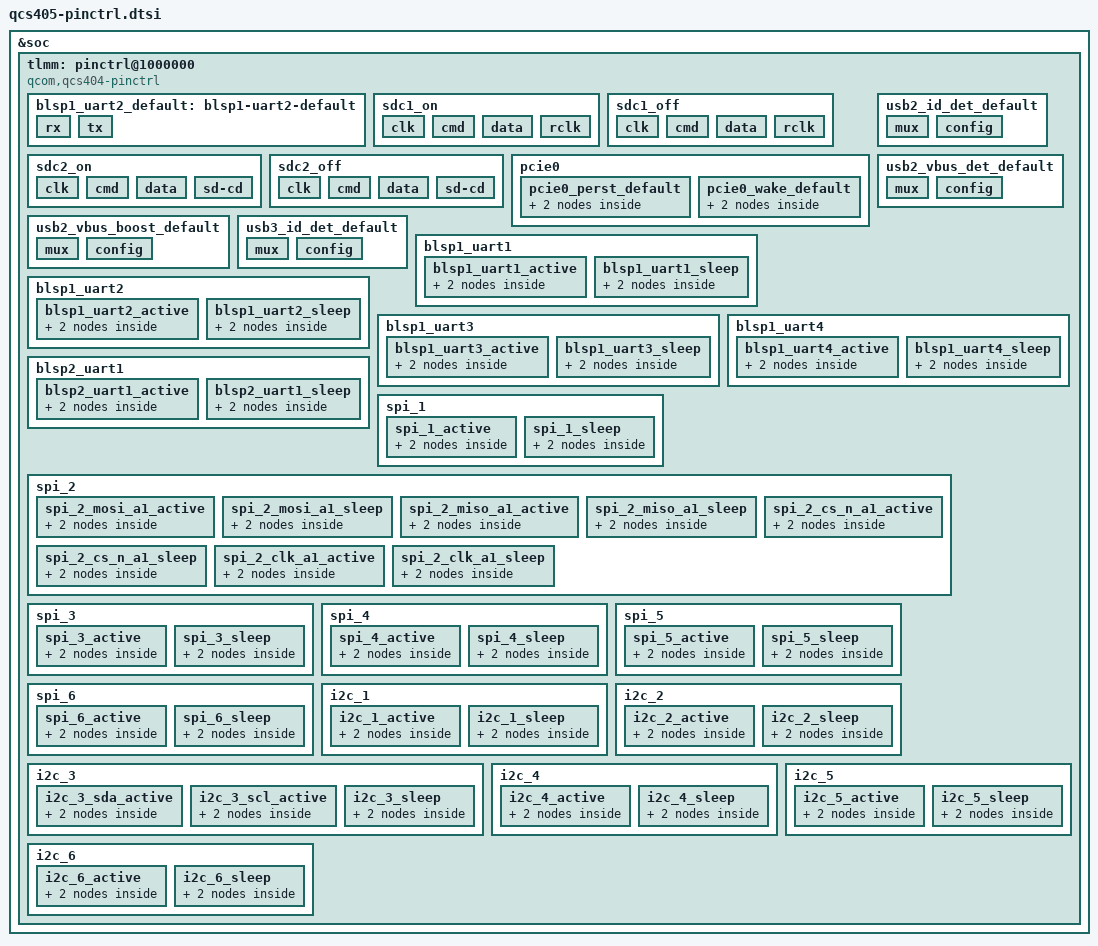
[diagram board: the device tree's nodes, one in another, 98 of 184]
&soc {
	tlmm: pinctrl@1000000 {
		compatible = "qcom,qcs404-pinctrl";
		reg = <0x01000000 0x200000>,
		      <0x01300000 0x200000>,
		      <0x07b00000 0x200000>;
		reg-names = "south", "north", "east";
		interrupts = <GIC_SPI 208 IRQ_TYPE_LEVEL_HIGH>;
		interrupt-controller;
		#interrupt-cells = <2>;
		gpio-ranges = <&tlmm 0 0 120>;
		gpio-controller;
		#gpio-cells = <2>;
		wakeup-parent = <&wakegic>;

		blsp1_uart2_default: blsp1-uart2-default {
			rx {
				pins = "gpio18";
				function = "blsp_uart_rx_a2";
			};

			tx {
				pins = "gpio17";
				function = "blsp_uart_tx_a2";
			};
		};

		sdc1_on: sdc1_on {
			clk {
				pins = "sdc1_clk";
				bias-disable;
				drive-strength = <16>;
			};

			cmd {
				pins = "sdc1_cmd";
				bias-pull-up;
				drive-strength = <10>;
			};

			data {
				pins = "sdc1_data";
				bias-pull-up;
				drive-strength = <10>;
			};

			rclk {
				pins = "sdc1_rclk";
				bias-pull-down;
			};
		};

		sdc1_off: sdc1_off {
			clk {
				pins = "sdc1_clk";
				bias-disable;
				drive-strength = <2>;
			};

			cmd {
				pins = "sdc1_cmd";
				bias-pull-up;
				drive-strength = <2>;
			};

			data {
				pins = "sdc1_data";
				bias-pull-up;
				drive-strength = <2>;
			};

			rclk {
				pins = "sdc1_rclk";
				bias-pull-down;
			};
		};

		sdc2_on: sdc2_on {
			clk {
				pins = "sdc2_clk";
				bias-disable;
				drive-strength = <16>;
			};

			cmd {
				pins = "sdc2_cmd";
				bias-pull-up;
				drive-strength = <10>;
			};

			data {
				pins = "sdc2_data";
				bias-pull-up;
				drive-strength = <10>;
			};

			sd-cd {
				pins = "gpio21";
				bias-pull-up;
				drive-strength = <2>;
			};
		};

		sdc2_off: sdc2_off {
			clk {
				pins = "sdc2_clk";
				bias-disable;
				drive-strength = <2>;
			};

			cmd {
				pins = "sdc2_cmd";
				bias-pull-up;
				drive-strength = <2>;
			};

			data {
				pins = "sdc2_data";
				bias-pull-up;
				drive-strength = <2>;
			};

			sd-cd {
				pins = "gpio21";
				bias-disable;
				drive-strength = <2>;
			};
		};

		pcie0 {
			pcie0_perst_default: pcie0_perst_default {
				mux {
					pins = "gpio43";
					function = "gpio";
				};

				config {
					pins = "gpio43";
					drive-strength = <2>;
					bias-disable;
				};
			};

			pcie0_wake_default: pcie0_wake_default {
				mux {
					pins = "gpio21";
					function = "gpio";
				};

				config {
					pins = "gpio21";
					drive-strength = <2>;
					bias-pull-down;
				};
			};
		};

		usb2_id_det_default: usb2_id_det_default {
			mux {
				pins = "gpio53";
				function = "gpio";
			};

			config {
				pins = "gpio53";
				drive-strength = <2>;
				bias-pull-up;
				input-enable;
			};
		};

		usb2_vbus_boost_default: usb2_vbus_boost_default {
			mux {
				pins = "gpio108";
				function = "gpio";
			};

			config {
				pins = "gpio108";
				drive-strength = <2>;
				bias-pull-down;
				output-low;
			};
		};

		usb2_vbus_det_default: usb2_vbus_det_default {
			mux {
				pins = "gpio116";
				function = "gpio";
			};

			config {
				pins = "gpio116";
				drive-strength = <2>;
				bias-pull-down;
				input-enable;
			};
		};

		usb3_id_det_default: usb3_id_det_default {
			mux {
				pins = "gpio113";
				function = "gpio";
			};

			config {
				pins = "gpio113";
				drive-strength = <2>;
				bias-pull-up;
				input-enable;
			};
		};

		/* UART configuration */
		blsp1_uart1 {
			blsp1_uart1_active: blsp1_uart1_active {
				mux {
					pins = "gpio30", "gpio31";
					function = "blsp_uart0";
				};

				config {
					pins = "gpio30", "gpio31";
					drive-strength = <2>;
					bias-disable;
				};
			};

			blsp1_uart1_sleep: blsp1_uart1_sleep {
				mux {
					pins = "gpio30", "gpio31";
					function = "gpio";
				};

				config {
					pins = "gpio30", "gpio31";
					drive-strength = <2>;
					bias-disable;
				};
			};
		};

		blsp1_uart2 {
			blsp1_uart2_active: blsp1_uart2_active {
				mux {
					pins = "gpio22", "gpio23";
					function = "blsp_uart1";
				};

				config {
					pins = "gpio22", "gpio23";
					drive-strength = <2>;
					bias-disable;
				};
			};

			blsp1_uart2_sleep: blsp1_uart2_sleep {
				mux {
					pins = "gpio22", "gpio23";
					function = "gpio";
				};

				config {
					pins = "gpio22", "gpio23";
					drive-strength = <2>;
					bias-disable;
				};
			};
		};

		blsp1_uart3 {
			blsp1_uart3_active: blsp1_uart3_active {
				mux {
					pins = "gpio17", "gpio18",
						"gpio19", "gpio20";
					function = "blsp_uart2";
				};

				config {
					pins = "gpio17", "gpio18",
						"gpio19", "gpio20";
					drive-strength = <2>;
					bias-disable;
				};
			};

			blsp1_uart3_sleep: blsp1_uart3_sleep {
				mux {
					pins = "gpio17", "gpio18",
						"gpio19", "gpio20";
					function = "gpio";
				};

				config {
					pins = "gpio17", "gpio18",
						"gpio19", "gpio20";
					drive-strength = <2>;
					bias-disable;
				};
			};
		};

		blsp1_uart4 {
			blsp1_uart4_active: blsp1_uart4_active {
				mux {
					pins = "gpio82", "gpio83";
					function = "blsp_uart3";
				};

				config {
					pins = "gpio82", "gpio83";
					drive-strength = <2>;
					bias-disable;
				};
			};

			blsp1_uart4_sleep: blsp1_uart4_sleep {
				mux {
					pins = "gpio82", "gpio83";
					function = "gpio";
				};

				config {
					pins = "gpio82", "gpio83";
					drive-strength = <2>;
					bias-disable;
				};
			};
		};

		blsp2_uart1 {
			blsp2_uart1_active: blsp2_uart1_active {
				mux {
					pins = "gpio26", "gpio27",
						"gpio28", "gpio29";
					function = "blsp_uart5";
				};

				config {
					pins = "gpio26", "gpio27",
						"gpio28", "gpio29";
					drive-strength = <2>;
					bias-disable;
				};
			};

			blsp2_uart1_sleep: blsp2_uart1_sleep {
				mux {
					pins = "gpio26", "gpio27",
						"gpio28", "gpio29";
					function = "gpio";
				};

				config {
					pins = "gpio26", "gpio27",
						"gpio28", "gpio29";
					drive-strength = <2>;
					bias-disable;
				};
			};
		};

		/* SPI CONFIGURATION */
		spi_1 {
			spi_1_active: spi_1_active {
				mux {
					pins = "gpio30", "gpio31",
						"gpio32", "gpio33";
					function = "blsp_spi0";
				};

				config {
					pins = "gpio30", "gpio31",
						"gpio32", "gpio33";
					drive-strength = <6>;
					bias-disable;
				};
			};

			spi_1_sleep: spi_1_sleep {
				mux {
					pins = "gpio30", "gpio31",
						"gpio32", "gpio33";
					function = "blsp_spi0";
				};

				config {
					pins = "gpio30", "gpio31",
						"gpio32", "gpio33";
					drive-strength = <6>;
					bias-disable;
				};
			};
		};

		spi_2 {
			spi_2_mosi_a1_active: spi_2_mosi_a1_active {
				mux {
					pins = "gpio22";
					function = "blsp_spi_mosi_a1";
				};

				config {
					pins = "gpio22";
					drive-strength = <6>;
					bias-disable;
				};
			};

			spi_2_mosi_a1_sleep: spi_2_mosi_a1_sleep {
				mux {
					pins = "gpio22";
					function = "blsp_spi_mosi_a1";
				};

				config {
					pins = "gpio22";
					drive-strength = <6>;
					bias-disable;
				};
			};

			spi_2_miso_a1_active: spi_2_miso_a1_active {
				mux {
					pins = "gpio23";
					function = "blsp_spi_miso_a1";
				};

				config {
					pins = "gpio23";
					drive-strength = <6>;
					bias-disable;
				};
			};

			spi_2_miso_a1_sleep: spi_2_miso_a1_sleep {
				mux {
					pins = "gpio23";
					function = "blsp_spi_miso_a1";
				};

				config {
					pins = "gpio23";
					drive-strength = <6>;
					bias-disable;
				};
			};

			spi_2_cs_n_a1_active: spi_2_cs_n_a1_active {
				mux {
					pins = "gpio24";
					function = "blsp_spi_cs_n_a1";
				};

				config {
					pins = "gpio24";
					drive-strength = <6>;
					bias-disable;
				};
			};

			spi_2_cs_n_a1_sleep: spi_2_cs_n_a1_sleep {
				mux {
					pins = "gpio24";
					function = "blsp_spi_cs_n_a1";
				};

				config {
					pins = "gpio24";
					drive-strength = <6>;
					bias-disable;
				};
			};

			spi_2_clk_a1_active: spi_2_clk_a1_active {
				mux {
					pins = "gpio25";
					function = "blsp_spi_clk_a1";
				};

				config {
					pins = "gpio25";
					drive-strength = <6>;
					bias-disable;
				};
			};

			spi_2_clk_a1_sleep: spi_2_clk_a1_sleep {
				mux {
					pins = "gpio25";
					function = "blsp_spi_clk_a1";
				};

				config {
					pins = "gpio25";
					drive-strength = <6>;
					bias-disable;
				};
			};
		};

		spi_3 {
			spi_3_active: spi_3_active {
				mux {
					pins = "gpio17", "gpio18",
						"gpio19", "gpio20";
					function = "blsp_spi2";
				};

				config {
					pins = "gpio17", "gpio18",
						"gpio19", "gpio20";
					drive-strength = <6>;
					bias-disable;
				};
			};

			spi_3_sleep: spi_3_sleep {
				mux {
					pins = "gpio17", "gpio18",
						"gpio19", "gpio20";
					function = "blsp_spi2";
				};

				config {
					pins = "gpio17", "gpio18",
						"gpio19", "gpio20";
					drive-strength = <6>;
					bias-disable;
				};
			};
		};

		spi_4 {
			spi_4_active: spi_4_active {
				mux {
					pins = "gpio82", "gpio83",
						"gpio84", "gpio85";
					function = "blsp_spi3";
				};

				config {
					pins = "gpio82", "gpio83",
						"gpio84", "gpio85";
					drive-strength = <6>;
					bias-disable;
				};
			};

			spi_4_sleep: spi_4_sleep {
				mux {
					pins = "gpio82", "gpio83",
						"gpio84", "gpio85";
					function = "blsp_spi3";
				};

				config {
					pins = "gpio82", "gpio83",
						"gpio84", "gpio85";
					drive-strength = <6>;
					bias-disable;
				};
			};
		};

		spi_5 {
			spi_5_active: spi_5_active {
				mux {
					pins = "gpio37", "gpio38",
						"gpio117", "gpio118";
					function = "blsp_spi4";
				};

				config {
					pins = "gpio37", "gpio38",
						"gpio117", "gpio118";
					drive-strength = <6>;
					bias-disable;
				};
			};

			spi_5_sleep: spi_5_sleep {
				mux {
					pins = "gpio37", "gpio38",
							"gpio117", "gpio118";
					function = "blsp_spi4";
				};

				config {
					pins = "gpio37", "gpio38",
						"gpio117", "gpio118";
					drive-strength = <6>;
					bias-disable;
				};
			};
		};

		spi_6 {
			spi_6_active: spi_6_active {
				mux {
					pins = "gpio26", "gpio27",
						"gpio28", "gpio29";
					function = "blsp_spi5";
				};

				config {
					pins = "gpio26", "gpio27",
						"gpio28", "gpio29";
					drive-strength = <6>;
					bias-disable;
				};
			};

			spi_6_sleep: spi_6_sleep {
				mux {
					pins = "gpio26", "gpio27",
						"gpio28", "gpio29";
					function = "blsp_spi5";
				};

				config {
					pins = "gpio26", "gpio27",
						"gpio28", "gpio29";
					drive-strength = <6>;
					bias-disable;
				};
			};
		};

		/* I2C configuration */
		i2c_1 {
			i2c_1_active: i2c_1_active {
				/* active state */
				mux {
					pins = "gpio32", "gpio33";
					function = "blsp_i2c0";
				};

				config {
					pins = "gpio32", "gpio33";
					drive-strength = <2>;
					bias-disable;
				};
			};

			i2c_1_sleep: i2c_1_sleep {
				/* suspended state */
				mux {
					pins = "gpio32", "gpio33";
					function = "gpio";
				};

				config {
					pins = "gpio32", "gpio33";
					drive-strength = <2>;
					bias-disable;
				};
			};
		};

		i2c_2 {
			i2c_2_active: i2c_2_active {
				/* active state */
				mux {
					pins = "gpio24", "gpio25";
					function = "blsp_i2c1";
				};

				config {
					pins = "gpio24", "gpio25";
					drive-strength = <2>;
					bias-disable;
				};
			};

			i2c_2_sleep: i2c_2_sleep {
				/* suspended state */
				mux {
					pins = "gpio24", "gpio25";
					function = "gpio";
				};

				config {
					pins = "gpio24", "gpio25";
					drive-strength = <2>;
					bias-disable;
				};
			};
		};

		i2c_3 {
			i2c_3_sda_active: i2c_3_sda_active {
				/* active state */
				mux {
					pins = "gpio19";
					function = "blsp_i2c_sda_a2";
				};

				config {
					pins = "gpio19";
					drive-strength = <2>;
					bias-disable;
				};
			};

			i2c_3_scl_active: i2c_3_scl_active {
				/* active state */
				mux {
					pins = "gpio20";
					function = "blsp_i2c_scl_a2";
				};

				config {
					pins = "gpio20";
					drive-strength = <2>;
					bias-disable;
				};
			};

			i2c_3_sleep: i2c_3_sleep {
				/* suspended state */
				mux {
					pins = "gpio19", "gpio20";
					function = "gpio";
				};

				config {
					pins = "gpio19", "gpio20";
					drive-strength = <2>;
					bias-disable;
				};
			};
		};

		i2c_4 {
			i2c_4_active: i2c_4_active {
				/* active state */
				mux {
					pins = "gpio84", "gpio85";
					function = "blsp_i2c3";
				};

				config {
					pins = "gpio84", "gpio85";
					drive-strength = <2>;
					bias-disable;
				};
			};

			i2c_4_sleep: i2c_4_sleep {
				/* suspended state */
				mux {
					pins = "gpio84", "gpio85";
					function = "gpio";
				};

				config {
					pins = "gpio84", "gpio85";
					drive-strength = <2>;
					bias-disable;
				};
			};
		};

		i2c_5 {
			i2c_5_active: i2c_5_active {
				/* active state */
				mux {
					pins = "gpio117", "gpio118";
					function = "blsp_i2c4";
				};

				config {
					pins = "gpio117", "gpio118";
					drive-strength = <2>;
					bias-disable;
				};
			};

			i2c_5_sleep: i2c_5_sleep {
				/* suspended state */
				mux {
					pins = "gpio117", "gpio118";
					function = "gpio";
				};

				config {
					pins = "gpio117", "gpio118";
					drive-strength = <2>;
					bias-disable;
				};
			};
		};

		i2c_6 {
			i2c_6_active: i2c_6_active {
				/* active state */
				mux {
					pins = "gpio28", "gpio29";
					function = "blsp_i2c5";
				};

				config {
					pins = "gpio28", "gpio29";
					drive-strength = <2>;
					bias-disable;
				};
			};

			i2c_6_sleep: i2c_6_sleep {
				/* suspended state */
				mux {
					pins = "gpio28", "gpio29";
					function = "gpio";
				};

				config {
					pins = "gpio28", "gpio29";
					drive-strength = <2>;
					bias-disable;
				};
			};
		};

	};
};
